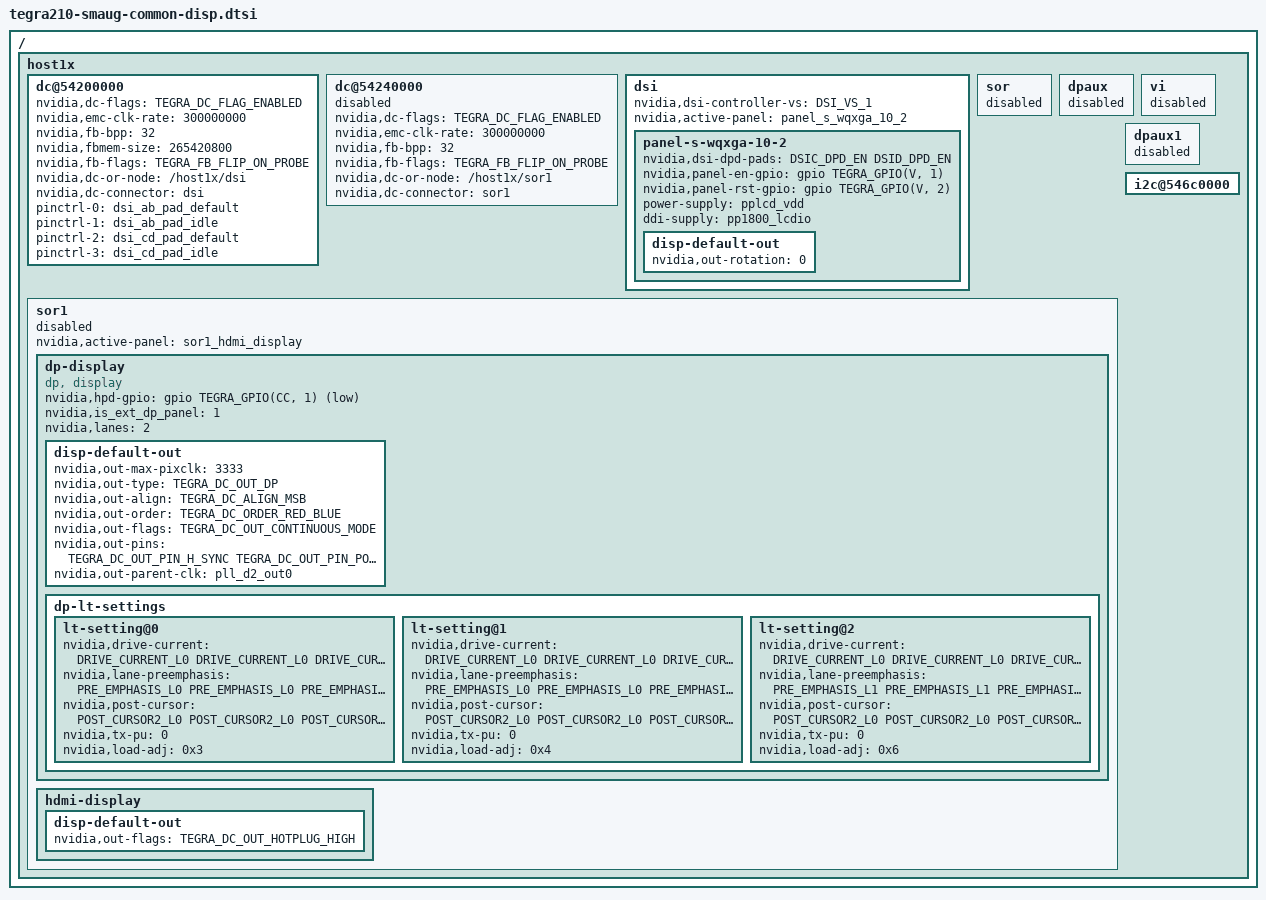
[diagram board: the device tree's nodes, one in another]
/*
 * arch/arm64/boot/dts/tegra210-smaug-common-disp.dtsi
 *
 * Copyright (c) 2016-2017, NVIDIA CORPORATION.  All rights reserved.
 *
 * This program is free software; you can redistribute it and/or modify
 * it under the terms of the GNU General Public License as published by
 * the Free Software Foundation; version 2 of the License.
 *
 * This program is distributed in the hope that it will be useful, but WITHOUT
 * ANY WARRANTY; without even the implied warranty of MERCHANTABILITY or
 * FITNESS FOR A PARTICULAR PURPOSE.  See the GNU General Public License for
 * more details.
 *
 */

#include "smaug-platforms/panel-s-wqxga-10-2.dtsi"
//#include <t210-common-platforms/tegra210-ers-hdmi-e2190-1100-a00.dtsi>

/ {
	host1x {
		status = "okay";
		/* tegradc.0 */
		dc@54200000 {
			status = "okay";
			nvidia,dc-flags = <TEGRA_DC_FLAG_ENABLED>;
			nvidia,emc-clk-rate = <300000000>;
			nvidia,fb-bpp = <32>; /* bits per pixel */
			nvidia,fbmem-size = <265420800>;
			nvidia,fb-flags = <TEGRA_FB_FLIP_ON_PROBE>;
			nvidia,dc-or-node = "/host1x/dsi";
			nvidia,dc-connector = <&dsi>;
			pinctrl-names = "pad_ab_default", "pad_ab_idle",
				"pad_cd_default", "pad_cd_idle";
			pinctrl-0 = <&dsi_ab_pad_default>;
			pinctrl-1 = <&dsi_ab_pad_idle>;
			pinctrl-2 = <&dsi_cd_pad_default>;
			pinctrl-3 = <&dsi_cd_pad_idle>;
		};

		/* tegradc.1 */
		dc@54240000 {
			status = "disabled";
			nvidia,dc-flags = <TEGRA_DC_FLAG_ENABLED>;
			nvidia,emc-clk-rate = <300000000>;
			nvidia,fb-bpp = <32>; /* bits per pixel */
			nvidia,fb-flags = <TEGRA_FB_FLIP_ON_PROBE>;
			nvidia,dc-or-node = "/host1x/sor1";
			nvidia,dc-connector = <&sor1>;
		};

		dsi {
			nvidia,dsi-controller-vs = <DSI_VS_1>;
			status = "okay";
			nvidia,active-panel = <&panel_s_wqxga_10_2>;
			panel-s-wqxga-10-2 {
				status = "okay";
				nvidia,dsi-dpd-pads = <DSIC_DPD_EN DSID_DPD_EN>;
				nvidia,panel-en-gpio = <&gpio TEGRA_GPIO(V, 1) 0>; /* PV1 */
				nvidia,panel-rst-gpio = <&gpio TEGRA_GPIO(V, 2) 0>; /* PV2 */
				power-supply = <&pplcd_vdd>;
				ddi-supply = <&pp1800_lcdio>;
				disp-default-out {
					nvidia,out-rotation = <0>;
				};
			};
		};

		sor {
			status = "disabled"; //0x54540000 disabled-in-stok / disabled-in-abca / disabled-in-5.2
		};

		dpaux {
			status = "disabled"; //0x545c0000 disabled-in-stok / okay-in-abca / okey-in-5.2
		};

		vi {
			status = "disabled";
		};

		sor1 {
			status = "disabled"; //0x54580000 okay-in-stok / okay-in-abca / disabled-in-5.2
			nvidia,active-panel = <&sor1_hdmi_display>;
			dp-display {
				status = "okay";
				compatible = "dp, display";
				nvidia,hpd-gpio = <&gpio TEGRA_GPIO(CC, 1) 1>; /* PN7 */
				nvidia,is_ext_dp_panel = <1>;
				nvidia,lanes = <2>;
				disp-default-out {
					nvidia,out-max-pixclk = <3333>; /* KHZ2PICOS(300000) */
					nvidia,out-type = <TEGRA_DC_OUT_DP>;
					nvidia,out-align = <TEGRA_DC_ALIGN_MSB>;
					nvidia,out-order = <TEGRA_DC_ORDER_RED_BLUE>;
					nvidia,out-flags = <TEGRA_DC_OUT_CONTINUOUS_MODE>;
					nvidia,out-pins = <TEGRA_DC_OUT_PIN_H_SYNC TEGRA_DC_OUT_PIN_POL_LOW
							   TEGRA_DC_OUT_PIN_V_SYNC TEGRA_DC_OUT_PIN_POL_LOW
							   TEGRA_DC_OUT_PIN_PIXEL_CLOCK TEGRA_DC_OUT_PIN_POL_LOW
							   TEGRA_DC_OUT_PIN_DATA_ENABLE TEGRA_DC_OUT_PIN_POL_HIGH>;
					nvidia,out-parent-clk = "pll_d2_out0";
				};
				dp-lt-settings {
					lt-setting@0 {
						nvidia,drive-current = <DRIVE_CURRENT_L0 DRIVE_CURRENT_L0 DRIVE_CURRENT_L0 DRIVE_CURRENT_L0>;
						nvidia,lane-preemphasis = <PRE_EMPHASIS_L0 PRE_EMPHASIS_L0 PRE_EMPHASIS_L0 PRE_EMPHASIS_L0>;
						nvidia,post-cursor = <POST_CURSOR2_L0 POST_CURSOR2_L0 POST_CURSOR2_L0 POST_CURSOR2_L0>;
						nvidia,tx-pu = <0>;
						nvidia,load-adj = <0x3>;
					};
					lt-setting@1 {
						nvidia,drive-current = <DRIVE_CURRENT_L0 DRIVE_CURRENT_L0 DRIVE_CURRENT_L0 DRIVE_CURRENT_L0>;
						nvidia,lane-preemphasis = <PRE_EMPHASIS_L0 PRE_EMPHASIS_L0 PRE_EMPHASIS_L0 PRE_EMPHASIS_L0>;
						nvidia,post-cursor = <POST_CURSOR2_L0 POST_CURSOR2_L0 POST_CURSOR2_L0 POST_CURSOR2_L0>;
						nvidia,tx-pu = <0>;
						nvidia,load-adj = <0x4>;
					};
					lt-setting@2 {
						nvidia,drive-current = <DRIVE_CURRENT_L0 DRIVE_CURRENT_L0 DRIVE_CURRENT_L0 DRIVE_CURRENT_L0>;
						nvidia,lane-preemphasis = <PRE_EMPHASIS_L1 PRE_EMPHASIS_L1 PRE_EMPHASIS_L1 PRE_EMPHASIS_L1>;
						nvidia,post-cursor = <POST_CURSOR2_L0 POST_CURSOR2_L0 POST_CURSOR2_L0 POST_CURSOR2_L0>;
						nvidia,tx-pu = <0>;
						nvidia,load-adj = <0x6>;
					};
				};
			};
			hdmi-display {
				status = "okay";
				disp-default-out {
					nvidia,out-flags = <TEGRA_DC_OUT_HOTPLUG_HIGH>;
				};
			};
		};

		dpaux1 {
			status = "disabled"; // 0x54040000 okay-in-stok / okay-in-abca / disabled-in-5.2
		};

		i2c@546c0000 {
			status = "okay";
		};
	};
};
